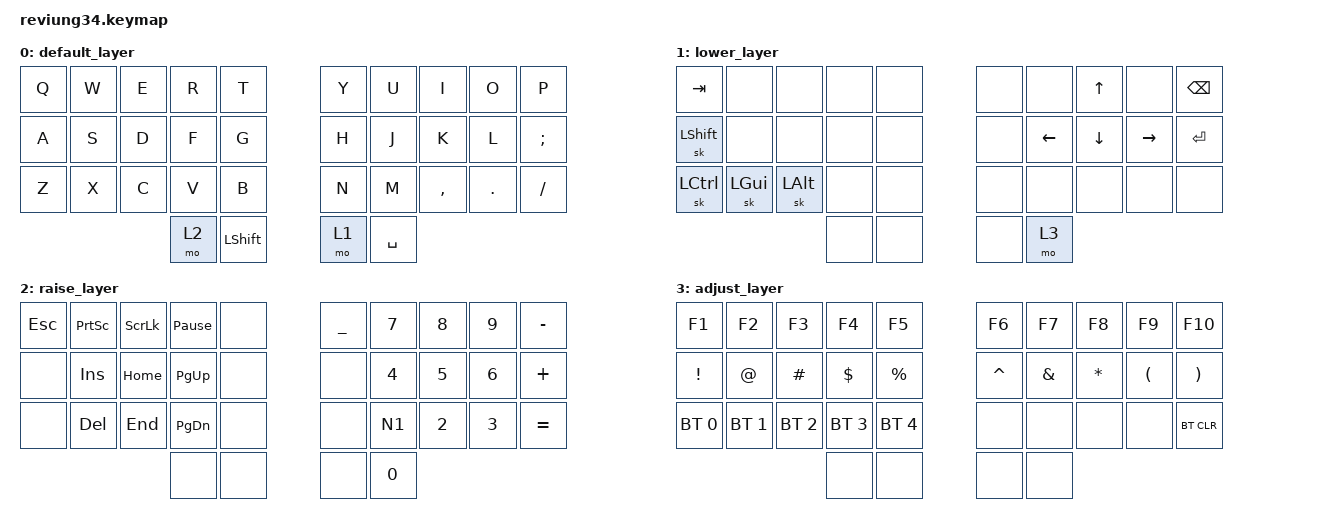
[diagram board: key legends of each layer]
#include <behaviors.dtsi>
#include <dt-bindings/zmk/keys.h>
#include <dt-bindings/zmk/bt.h>

/ {
    keymap {
        compatible = "zmk,keymap";

        default_layer {
// --------------------------------------------------------------------------------------------------------------------------------------------------------------------
// |   Q    |    W    |    E    |    R   |    T    |                                    |    Y    |    U    |    I    |    O    |    P    |
// |   A    |    S    |    D    |    F   |    G    |                                    |    H    |    J    |    K    |    L    |    ;    |
// |   Z    |    X    |    C    |    V   |    B    |  		 	                        |    N    |    M    |    ,    |    .    |    /    |
//                    |   RSE   |   LWR  |   SHFT  |  		    	                    |  SPACE  |
            bindings = <

     
    &kp Q     &kp W    &kp E     &kp R     &kp T                                            &kp Y     &kp U     &kp I     &kp O     &kp P 
    &kp A     &kp S    &kp D     &kp F     &kp G                                            &kp H     &kp J     &kp K     &kp L     &kp SEMI 
    &kp Z     &kp X    &kp C     &kp V     &kp B      	 			                        &kp N     &kp M     &kp COMMA &kp DOT   &kp FSLH 
                       &mo 2     &kp LSHFT &mo 1     			                	        &kp SPC   
                        >;
                };

                lower_layer {
// --------------------------------------------------------------------------------------------------------------------------------------------------------------------
// |   TAB    |         |         |        |         |                                   |         |         |    UP    |         |   BKSP  |
// |   SHFT    |         |         |        |         |                                   |         |   LFT   |    DWN   |   RGT   |   RET   |
// |   CTRL   |   GUI   |   ALT   |        |         |  		 	                     |         |         |          |         |         |
//                      |         |  LWR   |         |  		    	                 |   ADJ   |
            bindings = <

     
    &kp TAB     &none  &none  &none  &none                                            &none  &none  &kp UP  &none  &kp  BSPC
    &sk LSHFT    &none  &none  &none  &none                                            &none  &kp LEFT  &kp DOWN  &kp RIGHT  &kp RET 
    &sk LCTRL   &sk LGUI    &sk LALT   &none       &none        	 			      &none  &none  &none  &none  &none   
                       &none      &none       &none     			    	          &mo 3   
                        >;
                };

                raise_layer {
// --------------------------------------------------------------------------------------------------------------------------------------------------------------------
// | ESC    |  PRSC | SLCK | PAUSE|         |                                    |  _   |  7  |  8  |  9  |  -  |
// |        |  INS  | HOME | PGUP |         |                                    |     |  4  |  5  |  6  |  +  |
// |        |  DEL  |  END | PGDN |         |  		 	                         |     |  1  |  2  |  3  |  =  |
//                    |    RSE    |        |         |  		    	                    |  0  |
            bindings = <

     
    &kp ESC  &kp PSCRN  &kp SLCK  &kp PAUSE_BREAK     &none                                             &kp UNDER      &kp N7  &kp N8  &kp N9  &kp MINUS 
    &none  &kp INS    &kp HOME  &kp PG_UP     &none                                             &none      &kp N4  &kp N5  &kp N6  &kp PLUS   
    &none  &kp DEL    &kp END   &kp PG_DN     &none        	 			                        &none N1  &kp N2  &kp N3  &kp EQUAL 
                       &none  &none  &none      				                        &kp N0   
                        >;
                };
                
                adjust_layer {
// --------------------------------------------------------------------------------------------------------------------------------------------------------------------
// |    F1   |   F2   |   F3   |   F4   |   F5    |                                |   F6    |   F7    |   F8    |   F9    |   F10     |
// |    !    |    @   |    #   |   $    |    %    |                                |    ^    |    &    |    *    |    (    |    )      |
// |   BT1   |   BT2  |   BT3  |   BT4  |   BT5   |  		 	                   |         |         |         |         |  BT CLR   |
//                    |        |   ADJ  |         |  		                       |  ADJ    |
            bindings = <

     
    &kp F1    &kp F2    &kp F3    &kp F4    &kp F5     &kp F6     &kp F7    &kp F8     &kp F9    &kp F10
    &kp EXCL  &kp AT    &kp HASH  &kp DLLR  &kp PRCNT  &kp CARET  &kp AMPS  &kp ASTRK  &kp LPAR  &kp RPAR
    &bt BT_SEL 0     &bt BT_SEL 1     &bt BT_SEL 2     &bt BT_SEL 3     &bt BT_SEL 4     &none &none &none &none &bt BT_CLR
                       &none  &none  &none                                          &none   
                        >;
                };
        };
};
